# nrf5340_application register map
Vendor: Nordic Semiconductor; Series: nrf53; File version: 1
CPU: CM33 r0p4, little endian, MPU, FPU, 3 interrupt priority bits, 69 interrupts
Registers are 32-bit, read-write, reset 0x0 unless marked. A register's access mark holds for its fields unless they carry their own. Offsets are from the block's base; [hi:lo] are bit positions; lines under a group give offsets from that group; {n}, {i} and the like mark numbered series.

## CC_GHASH_S — CRYPTOCELL GHASH engine
Base 0x50845000; alternate view of CC_AES_S
{0x960+4i} GHASH_SUBKEY[{i}] (i=0..3) wo — Description collection: GHASH subkey value to use. The initial GHASH_SUBKEY[0] register holds the least significant bits [31:0] of the subkey value.
  [31:0] VALUE — GHASH subkey value.
{0x970+4i} GHASH_IV[{i}] (i=0..3) — Description collection: GHASH Initialization Vector (IV) to use. The initial GHASH_IV[0] register holds the least significant bits [31:0] of the IV.
  [31:0] VALUE — GHASH IV value.
0x980 GHASH_BUSY ro — Status register for GHASH engine activity.
  [0] STATUS — GHASH engine status.
    0=Idle (GHASH engine is idle); 1=Busy (GHASH engine is busy)
0x984 GHASH_INIT wo — Configure the GHASH engine for a new GHASH operation.
  [0] ENABLE — Initialize a new GHASH operation.
    1=Enable (Initialize GHASH operation)

## CC_MISC_S — CRYPTOCELL MISC interface
Base 0x50845000; alternate view of CC_AES_S
0x810 AES_CLK wo — Clock control for the AES engine.
  [0] ENABLE — Enables clock for the AES engine.
    0=Disable clock for the AES engine; 1=Enable clock for the AES engine
0x818 HASH_CLK wo — Clock control for the HASH engine.
  [0] ENABLE — Enables clock for the HASH engine.
    0=Disable clock for the HASH engine; 1=Enable clock for the HASH engine
0x81C PKA_CLK wo — Clock control for the PKA engine.
  [0] ENABLE — Enables clock for the PKA engine.
    0=Disable clock for the PKA engine; 1=Enable clock for the PKA engine
0x820 DMA_CLK wo — Clock control for the DMA engines.
  [0] ENABLE — Enables clock for the DMA engines.
    0=Disable clock for the DMA engines; 1=Enable clock for the DMA engines
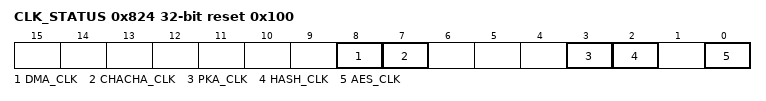
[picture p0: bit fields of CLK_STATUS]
0x824 CLK_STATUS ro reset 0x100 — CRYPTOCELL clocks status register.
  [8] DMA_CLK — Status of DMA engines clock.
    0=Disabled (Clocks for DMA engines are disabled); 1=Enabled (Clocks for DMA engines are enabled)
  [7] CHACHA_CLK — Status of CHACHA engine clock.
    0=Disabled (Clock for CHACHA engine is disabled); 1=Enabled (Clock for CHACHA engine is enabled)
  [3] PKA_CLK — Status of PKA engine clock.
    0=Disabled (Clock for PKA engine is disabled); 1=Enabled (Clock for PKA engine is enabled)
  [2] HASH_CLK — Status of HASH engine clock.
    0=Disabled (Clock for HASH engine is disabled); 1=Enabled (Clock for HASH engine is enabled)
  [0] AES_CLK — Status of AES engine clock.
    0=Disabled (Clock for AES engine is disabled); 1=Enabled (Clock for AES engine is enabled)
0x858 CHACHA_CLK wo — Clock control for the CHACHA engine.
  [0] ENABLE — Enables clock for the CHACHA engine.
    0=Disable clock for the CHACHA engine; 1=Enable clock for the CHACHA engine

## CC_RNG_SRAM_S — CRYPTOCELL RNG SRAM interface
Base 0x50845000; alternate view of CC_AES_S
0xF00 SRAM_DATA — Read/Write data from RNG SRAM
  [31:0] SRAM_DATA — 32 bits DMA read/write from/to RNG SRAM. A 'read' or 'write' operation to this register will trigger the DMA address to be automatically incremented.
0xF04 SRAM_ADDR wo — First address given to RNG SRAM DMA for read/write transactions from/to RNG SRAM.
  [14:0] SRAM_ADDR — RNG SRAM starting address
0xF08 SRAM_DATA_READY ro reset 0x1 — RNG SRAM DMA engine is ready to read/write from/to RNG SRAM.
  [0] SRAM_READY — RNG SRAM DMA status.
    0=Busy (DMA is busy); 1=Idle (DMA is idle)

## VMC_NS — Volatile Memory controller 0
Base 0x40081000
Same registers: VMC_S 0x50081000
{0x600+0x10*i} RAM[{i}] (i=0..7) group — Unspecified
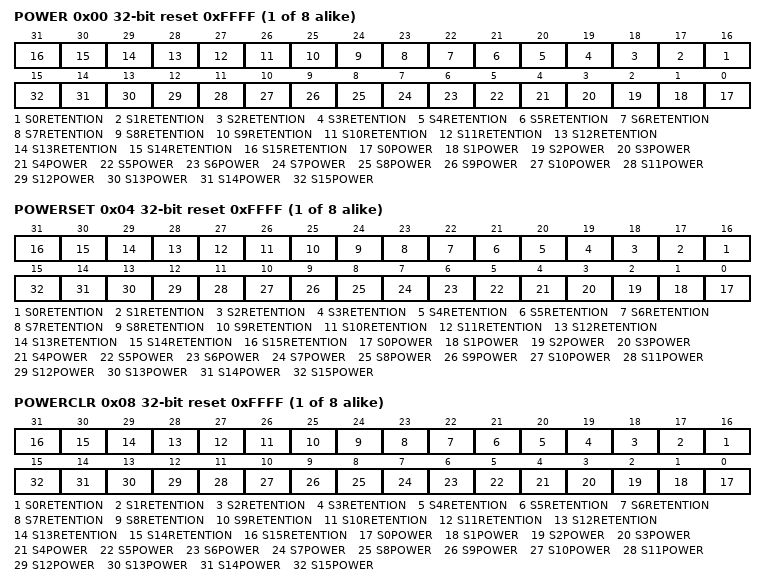
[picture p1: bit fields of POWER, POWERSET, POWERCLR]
  0x00 POWER reset 0xFFFF — Description cluster: RAM[n] power control register
    [all] fields
      0=Off; 1=On
    [n+16] S{n}RETENTION (n=0..15) — Keep retention on RAM section S{n} of RAM[n] when RAM section is switched off
    [n] S{n}POWER (n=0..15) — Keep RAM section S{n} of RAM[n] on or off in System ON mode
  0x04 POWERSET reset 0xFFFF — Description cluster: RAM[n] power control set register
    [all] fields
      1=On
    [n+16] S{n}RETENTION (n=0..15) — Keep retention on RAM section S{n} of RAM[n] when RAM section is switched off
    [n] S{n}POWER (n=0..15) — Keep RAM section S{n} of RAM[n] on or off in System ON mode
  0x08 POWERCLR reset 0xFFFF — Description cluster: RAM[n] power control clear register
    [all] fields
      1=Off
    [n+16] S{n}RETENTION (n=0..15) — Keep retention on RAM section S{n} of RAM[n] when RAM section is switched off
    [n] S{n}POWER (n=0..15) — Keep RAM section S{n} of RAM[n] on or off in System ON mode
